# EFR32MR21A020F512IM32 register map
Vendor: Silicon Labs; Series: EFR32; File version: D
Registers are 32-bit, read-write, reset 0x0 unless marked. A register's access mark holds for its fields unless they carry their own. Offsets are from the block's base; [hi:lo] are bit positions; {n}, {i} and the like mark numbered series; 'fields as' and 'values as' point back to an identical list.

## MSC_NS — MSC_NS Registers
Base 0x50030000
Same registers: MSC_S 0x40030000
0x00 IPVERSION ro reset 0x6
  [31:0] IPVERSION — IP Version ID
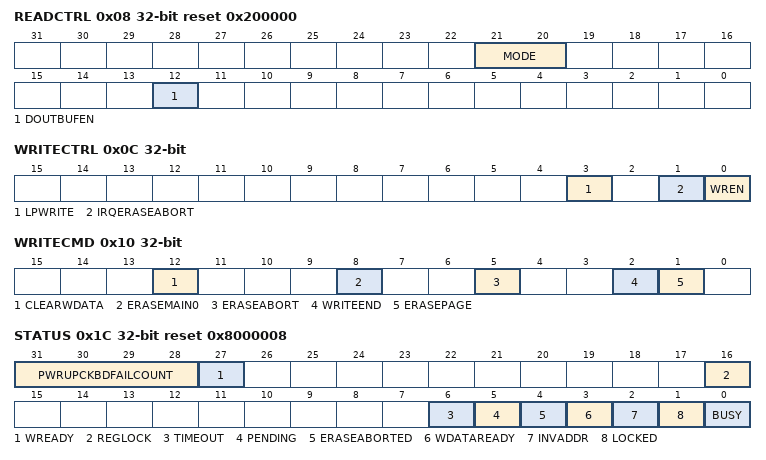
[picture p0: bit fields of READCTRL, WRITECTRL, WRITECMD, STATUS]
0x08 READCTRL reset 0x200000
  [21:20] MODE — Read Mode
    0=WS0 (Zero wait-states inserted in fetch or read transfers); 1=WS1 (One wait-state inserted for each fetch or read transfer. See Flash Wait-States table for details); 2=WS2 (Two wait-states inserted for eatch fetch or read transfer. See Flash Wait-States table for details); 3=WS3 (Three wait-states inserted for eatch fetch or read transfer. See Flash Wait-States table for details)
  [12] DOUTBUFEN — Flash dout pipeline buffer enable
0x0C WRITECTRL
  [3] LPWRITE — Low-Power Write
  [1] IRQERASEABORT — Abort Page Erase on Interrupt
  [0] WREN — Enable Write/Erase Controller
0x10 WRITECMD wo
  [12] CLEARWDATA — Clear WDATA state
  [8] ERASEMAIN0 — Mass erase region 0
  [5] ERASEABORT — Abort erase sequence
  [2] WRITEEND — End Write Mode
  [1] ERASEPAGE
0x14 ADDRB
  [31:0] ADDRB — Page Erase or Write Address Buffer
0x18 WDATA
  [31:0] DATAW — Write Data
0x1C STATUS ro reset 0x8000008
  [31:28] PWRUPCKBDFAILCOUNT — Flash power up checkerboard pattern chec
  [27] WREADY — Flash Write Ready
  [16] REGLOCK — Register Lock Status
    0=UNLOCKED; 1=LOCKED
  [6] TIMEOUT — Write Command Timeout
  [5] PENDING — Write Command In Queue
  [4] ERASEABORTED — Erase Operation Aborted
  [3] WDATAREADY — WDATA Write Ready
  [2] INVADDR — Invalid Write Address or Erase Page
  [1] LOCKED — Access Locked
  [0] BUSY — Erase/Write Busy
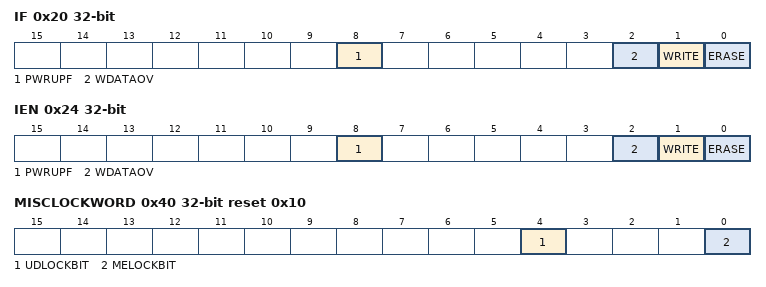
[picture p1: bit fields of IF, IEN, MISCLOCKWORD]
0x20 IF
  [8] PWRUPF — Flash Power Up Sequence Complete Flag
  [2] WDATAOV — Host write buffer overflow
  [1] WRITE — Host Write Done Interrupt Read Flag
  [0] ERASE — Host Erase Done Interrupt Read Flag
0x24 IEN
  [8] PWRUPF — Flash Power Up Sequence Complete
  [2] WDATAOV — write data buffer overflow irq enable
  [1] WRITE — Write Done Interrupt enable
  [0] ERASE — Erase Done Interrupt enable
0x34 USERDATASIZE ro reset 0x4
  [5:0] USERDATASIZE
0x38 CMD wo
  [0] PWRUP — Flash Power Up Command
0x3C LOCK wo
  [15:0] LOCKKEY — Configuration Lock
    0=LOCK; 0x1B71=UNLOCK
0x40 MISCLOCKWORD reset 0x10
  [4] UDLOCKBIT — User Data Lock
  [0] MELOCKBIT — Mass Erase Lock
{0x120+4i} PAGELOCK{i} (i=0..3)
  [31:0] LOCKBIT — page lock bit

## PRS_NS — PRS_NS Registers
Base 0x50038000
Same registers: PRS_S 0x40038000
0x00 IPVERSION ro
  [31:0] IPVERSION — IP version ID
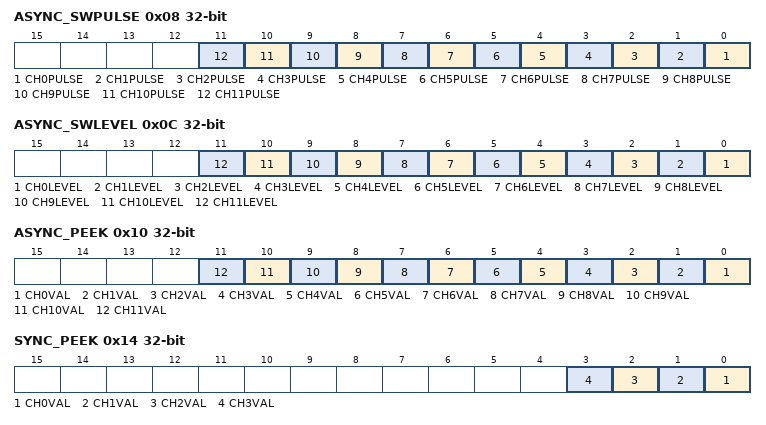
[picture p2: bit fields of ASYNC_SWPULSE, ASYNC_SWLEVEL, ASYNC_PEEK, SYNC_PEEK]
0x08 ASYNC_SWPULSE wo
  [n] CH{n}PULSE (n=0..11) — Channel pulse
0x0C ASYNC_SWLEVEL
  [n] CH{n}LEVEL (n=0..11) — Channel Level
0x10 ASYNC_PEEK ro
  [n] CH{n}VAL (n=0..11) — Channel {n} Current Value
0x14 SYNC_PEEK ro
  [n] CH{n}VAL (n=0..3) — Channel {n} Current Value
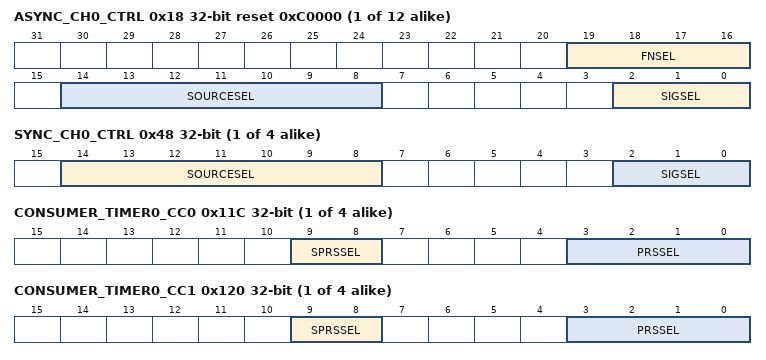
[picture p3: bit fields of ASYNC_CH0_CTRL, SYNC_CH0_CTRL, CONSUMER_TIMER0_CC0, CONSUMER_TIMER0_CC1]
{0x18+4i} ASYNC_CH{i}_CTRL reset 0xC0000 (i=0..11)
  [19:16] FNSEL — Function Select
    0=LOGICAL_ZERO (Logical 0); 1=A_NOR_B; 2=NOT_A_AND_B ((!A) AND B); 3=NOT_A (!A); 4=A_AND_NOT_B (A AND (!B)); 5=NOT_B (!B); 6=A_XOR_B; 7=A_NAND_B; 8=A_AND_B; 9=A_XNOR_B; 10=B; 11=NOT_A_OR_B ((!A) OR B); 12=A; 13=A_OR_NOT_B (A OR (!B)); 14=A_OR_B; 15=LOGICAL_ONE (Logical 1)
  [14:8] SOURCESEL — Source Select
  [2:0] SIGSEL — Signal Select
    0=NONE
{0x48+4i} SYNC_CH{i}_CTRL (i=0..3)
  [14:8] SOURCESEL — Source Select
  [2:0] SIGSEL — Signal Select
    0=NONE
0x58 CONSUMER_CMU_CALDN
  [3:0] PRSSEL — Asynchronous Channel Selection
0x5C CONSUMER_CMU_CALUP
  [3:0] PRSSEL — Asynchronous Channel Selection
0x6C CONSUMER_LDMAXBAR_DMAREQ0
  [3:0] PRSSEL — Asynchronous Channel Selection
0x70 CONSUMER_LDMAXBAR_DMAREQ1
  [3:0] PRSSEL — Asynchronous Channel Selection
0x74 CONSUMER_LETIMER0_CLEAR
  [3:0] PRSSEL — Asynchronous Channel Selection
0x78 CONSUMER_LETIMER0_START
  [3:0] PRSSEL — Asynchronous Channel Selection
0x7C CONSUMER_LETIMER0_STOP
  [3:0] PRSSEL — Asynchronous Channel Selection
0x80 CONSUMER_MODEM_DIN
  [3:0] PRSSEL — Asynchronous Channel Selection
0xB8 CONSUMER_RAC_CLR
  [3:0] PRSSEL — Asynchronous Channel Selection
0xBC CONSUMER_RAC_FORCETX
  [3:0] PRSSEL — Asynchronous Channel Selection
0xC0 CONSUMER_RAC_RXDIS
  [3:0] PRSSEL — Asynchronous Channel Selection
0xC4 CONSUMER_RAC_RXEN
  [3:0] PRSSEL — Asynchronous Channel Selection
0xC8 CONSUMER_RAC_SEQ
  [3:0] PRSSEL — Asynchronous Channel Selection
0xCC CONSUMER_RAC_TXEN
  [3:0] PRSSEL — Asynchronous Channel Selection
{0xD0+4i} CONSUMER_RTCC_CC{i} (i=0..2)
  [3:0] PRSSEL — Asynchronous Channel Selection
{0xE0+4i} CONSUMER_SE_TAMPERSRC{i} (i=0..7)
  [3:0] PRSSEL — Asynchronous Channel Selection
{0x108+4i} CONSUMER_CORE_CTIIN{i} (i=0..3)
  [3:0] PRSSEL — Asynchronous Channel Selection
0x118 CONSUMER_CORE_M33RXEV
  [3:0] PRSSEL — Asynchronous Channel Selection
{0x11C+0x18*i} CONSUMER_TIMER{i}_CC0 (i=0..3)
  [9:8] SPRSSEL — Synchronous Channel Selection
  [3:0] PRSSEL — Asynchronous Channel Selection
{0x120+0x18*i} CONSUMER_TIMER{i}_CC1 (i=0..3)
  fields as CONSUMER_TIMER0_CC0
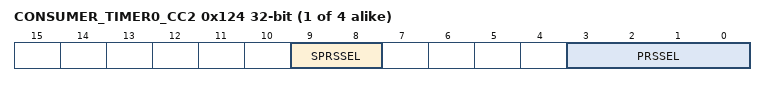
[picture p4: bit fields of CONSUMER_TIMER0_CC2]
{0x124+0x18*i} CONSUMER_TIMER{i}_CC2 (i=0..3)
  fields as CONSUMER_TIMER0_CC0
{0x128+0x18*i} CONSUMER_TIMER{i}_DTI (i=0..3)
  [3:0] PRSSEL — Asynchronous Channel Selection
{0x12C+0x18*i} CONSUMER_TIMER{i}_DTIFS1 (i=0..3)
  [3:0] PRSSEL — Asynchronous Channel Selection
{0x130+0x18*i} CONSUMER_TIMER{i}_DTIFS2 (i=0..3)
  [3:0] PRSSEL — Asynchronous Channel Selection
{0x17C+0x10*i} CONSUMER_USART{i}_CLK (i=0..2)
  [3:0] PRSSEL — Asynchronous Channel Selection
{0x180+0x10*i} CONSUMER_USART{i}_IR (i=0..2)
  [3:0] PRSSEL — Asynchronous Channel Selection
{0x184+0x10*i} CONSUMER_USART{i}_RX (i=0..2)
  [3:0] PRSSEL — Asynchronous Channel Selection
{0x188+0x10*i} CONSUMER_USART{i}_TRIGGER (i=0..2)
  [3:0] PRSSEL — Asynchronous Channel Selection
0x1AC CONSUMER_WDOG0_SRC0
  [3:0] PRSSEL — Asynchronous Channel Selection
0x1B0 CONSUMER_WDOG0_SRC1
  [3:0] PRSSEL — Asynchronous Channel Selection
0x1B4 CONSUMER_WDOG1_SRC0
  [3:0] PRSSEL — Asynchronous Channel Selection
0x1B8 CONSUMER_WDOG1_SRC1
  [3:0] PRSSEL — Asynchronous Channel Selection
